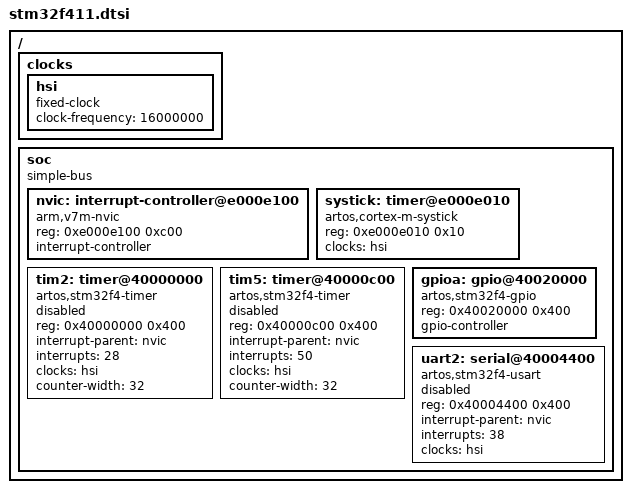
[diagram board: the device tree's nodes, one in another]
// Minimal supported device inventory; addresses and IRQs belong to the SoC.
/ {
    #address-cells = <1>;
    #size-cells = <1>;
    clocks {
        hsi: hsi {
            compatible = "fixed-clock";
            #clock-cells = <0>;
            clock-frequency = <16000000>;
        };
    };
    soc {
        compatible = "simple-bus";
        #address-cells = <1>;
        #size-cells = <1>;
        ranges;
        nvic: interrupt-controller@e000e100 {
            compatible = "arm,v7m-nvic";
            reg = <0xe000e100 0xc00>;
            interrupt-controller;
            #address-cells = <0>;
            #interrupt-cells = <1>;
        };
        systick: timer@e000e010 {
            compatible = "artos,cortex-m-systick";
            reg = <0xe000e010 0x10>;
            clocks = <&hsi>;
        };
        tim2: timer@40000000 {
            compatible = "artos,stm32f4-timer";
            reg = <0x40000000 0x400>;
            interrupt-parent = <&nvic>;
            interrupts = <28>;
            clocks = <&hsi>;
            counter-width = <32>;
            status = "disabled";
        };
        tim5: timer@40000c00 {
            compatible = "artos,stm32f4-timer";
            reg = <0x40000c00 0x400>;
            interrupt-parent = <&nvic>;
            interrupts = <50>;
            clocks = <&hsi>;
            counter-width = <32>;
            status = "disabled";
        };
        gpioa: gpio@40020000 {
            compatible = "artos,stm32f4-gpio";
            reg = <0x40020000 0x400>;
            gpio-controller;
            #gpio-cells = <2>;
        };
        uart2: serial@40004400 {
            compatible = "artos,stm32f4-usart";
            reg = <0x40004400 0x400>;
            interrupt-parent = <&nvic>;
            interrupts = <38>;
            clocks = <&hsi>;
            status = "disabled";
        };
    };
};
